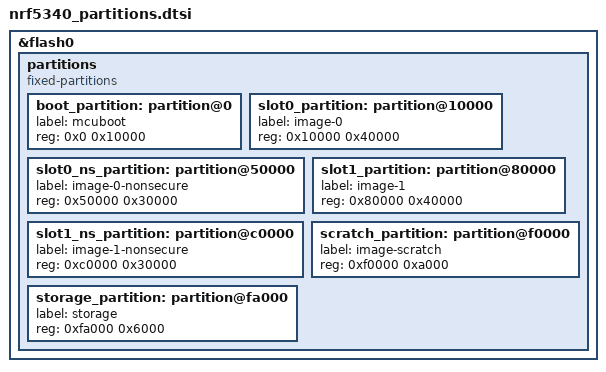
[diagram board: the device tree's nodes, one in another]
/*
 * Copyright (c) 2019-2020 Nordic Semiconductor ASA
 *
 * SPDX-License-Identifier: Apache-2.0
 */

/*
 * Default Flash planning for pill_nrf5340 CPUAPP (Application MCU).
 *
 * Zephyr build for nRF5340 with ARM TrustZone-M support,
 * implies building Secure and Non-Secure Zephyr images.
 *
 * Secure image will be placed, by default, in flash0
 * (or in slot0, if MCUboot is present).
 * Secure image will use sram0 for system memory.
 *
 * Non-Secure image will be placed in slot0_ns, and use
 * sram0_ns for system memory.
 *
 * Note that the Secure image only requires knowledge of
 * the beginning of the Non-Secure image (not its size).
 */

 &flash0 {
	partitions {
		compatible = "fixed-partitions";
		#address-cells = <1>;
		#size-cells = <1>;

		boot_partition: partition@0 {
			label = "mcuboot";
			reg = <0x0 0x10000>;
		};
		slot0_partition: partition@10000 {
			label = "image-0";
			reg = <0x10000 0x40000>;
		};
		slot0_ns_partition: partition@50000 {
			label = "image-0-nonsecure";
			reg = <0x50000 0x30000>;
		};
		slot1_partition: partition@80000 {
			label = "image-1";
			reg = <0x80000 0x40000>;
		};
		slot1_ns_partition: partition@c0000 {
			label = "image-1-nonsecure";
			reg = <0xc0000 0x30000>;
		};
		scratch_partition: partition@f0000 {
			label = "image-scratch";
			reg = <0xf0000 0xa000>;
		};
		storage_partition: partition@fa000 {
			label = "storage";
			reg = <0xfa000 0x6000>;
		};
	};
};

/* Include shared RAM configuration file */
#include "nrf5340_shared_sram.dtsi"
